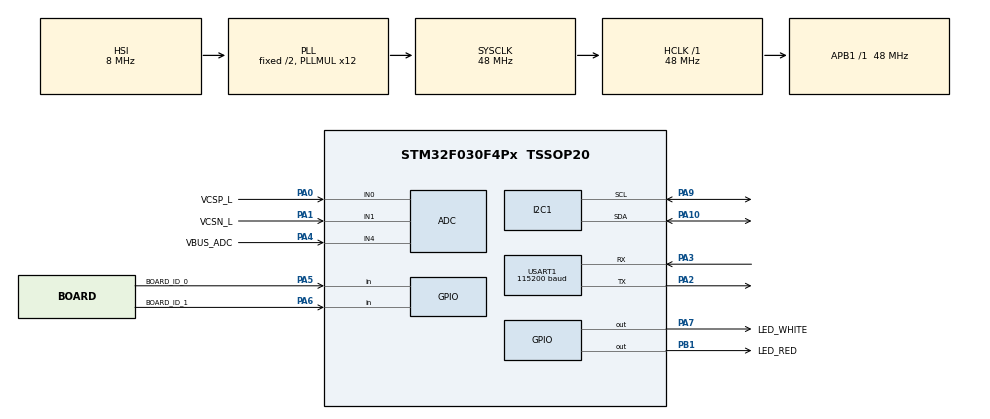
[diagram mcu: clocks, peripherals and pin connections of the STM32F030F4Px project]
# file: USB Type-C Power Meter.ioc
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ADC.SamplingTime=ADC_SAMPLETIME_239CYCLES_5
Mcu.Family=STM32F0
Mcu.Name=STM32F030F4Px
Mcu.Package=TSSOP20
PA0.GPIO_Label=VCSP_L
PA0.Mode=IN0
PA0.Signal=ADC_IN0
PA1.GPIO_Label=VCSN_L
PA1.Mode=IN1
PA1.Signal=ADC_IN1
PA10.Mode=I2C
PA10.Signal=I2C1_SDA
PA13.Mode=Serial_Wire
PA13.Signal=SYS_SWDIO
PA14.Mode=Serial_Wire
PA14.Signal=SYS_SWCLK
PA2.Mode=Asynchronous
PA2.Signal=USART1_TX
PA3.Mode=Asynchronous
PA3.Signal=USART1_RX
PA4.GPIO_Label=VBUS_ADC
PA4.Mode=IN4
PA4.Signal=ADC_IN4
PA5.GPIO_Label=BOARD_ID_0
PA5.Signal=GPIO_Input
PA6.GPIO_Label=BOARD_ID_1
PA6.Signal=GPIO_Input
PA7.GPIO_Label=LED_WHITE
PA7.Signal=GPIO_Output
PA9.Mode=I2C
PA9.Signal=I2C1_SCL
PB1.GPIO_Label=LED_RED
PB1.Signal=GPIO_Output
ProjectManager.HeapSize=0x200
ProjectManager.StackSize=0x400
ProjectManager.TargetToolchain=Makefile
RCC.AHBFreq_Value=48000000
RCC.APB1Freq_Value=48000000
RCC.APB1TimFreq_Value=48000000
RCC.HCLKFreq_Value=48000000
RCC.PLLMUL=RCC_PLL_MUL12
RCC.SYSCLKFreq_VALUE=48000000
RCC.SYSCLKSource=RCC_SYSCLKSOURCE_PLLCLK
USART1.BaudRate=115200
USART1.VirtualMode-Asynchronous=VM_ASYNC
board=custom

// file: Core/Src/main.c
/* USER CODE BEGIN Header */
/**
  ******************************************************************************
  * @file           : main.c
  * @brief          : Main program body
  ******************************************************************************
  * @attention
  *
  * Copyright (c) 2022 STMicroelectronics.
  * All rights reserved.
  *
  * This software is licensed under terms that can be found in the LICENSE file
  * in the root directory of this software component.
  * If no LICENSE file comes with this software, it is provided AS-IS.
  *
  ******************************************************************************
  */
/* USER CODE END Header */
#include "main.h"

/* USER CODE BEGIN Includes */
#include "board.h"
#include "light_rcc_init.h"
/* USER CODE END Includes */

/* USER CODE BEGIN PM */

I2C_HandleTypeDef hi2c1;

#if defined(UART_DEBUG) && !defined(UART_DEBUG_GPIO)
UART_HandleTypeDef huart1;
#endif

#if !defined(FIXED_SKUID) || (SKUID == SKUID_1)
ADC_HandleTypeDef hadc;
#endif

#if 0
/* USER CODE END PM */

ADC_HandleTypeDef hadc;

I2C_HandleTypeDef hi2c1;

UART_HandleTypeDef huart1;

/* USER CODE BEGIN PV */
#endif
/* USER CODE END PV */

void SystemClock_Config(void);
static void MX_GPIO_Init(void);
static void MX_ADC_Init(void);
static void MX_I2C1_Init(void);
static void MX_USART1_UART_Init(void);

/* USER CODE BEGIN 0 */
#include <stdio.h>
#include <string.h>
/* USER CODE END 0 */

int main(void)
{

  /* MCU Configuration--------------------------------------------------------*/

  /* Reset of all peripherals, Initializes the Flash interface and the Systick. */
  HAL_Init();

  /* USER CODE BEGIN Init */
#ifndef CONFIG_LIGHT_RCC_INIT
  /* USER CODE END Init */

  /* Configure the system clock */
  SystemClock_Config();

  /* USER CODE BEGIN SysInit */
#else
  Light_SystemClock_Config();
#endif
  /* USER CODE END SysInit */

  /* Initialize all configured peripherals */
  MX_GPIO_Init();
  MX_ADC_Init();
  MX_I2C1_Init();
  MX_USART1_UART_Init();
  /* USER CODE BEGIN 2 */

  BOARD_Init();
  PRINTF("Init Done\r\n");

  int tick_loop = HAL_GetTick();

#ifdef CONFIG_LED_NORMAL
  int tick_led = HAL_GetTick();
#endif
  /* USER CODE END 2 */

  /* Infinite loop */
  while (1)
  {

    /* USER CODE BEGIN 3 */
    if((HAL_GetTick() - tick_loop) >= CONFIG_BOARD_LOOP_TIME_MS) {
      tick_loop = HAL_GetTick();
      BOARD_Loop();
    }

#ifdef CONFIG_LED_NORMAL
    if((HAL_GetTick() - tick_led) >= CONFIG_LED_NORMAL_BLINK_MS) {
      tick_led = HAL_GetTick();
      HAL_GPIO_TogglePin(LED_BLUE_GPIO_Port, LED_BLUE_Pin);
    }
#endif

  }
  /* USER CODE END 3 */
}

void SystemClock_Config(void)
{
  RCC_OscInitTypeDef RCC_OscInitStruct = {0};
  RCC_ClkInitTypeDef RCC_ClkInitStruct = {0};
  RCC_PeriphCLKInitTypeDef PeriphClkInit = {0};

  /** Initializes the RCC Oscillators according to the specified parameters
  * in the RCC_OscInitTypeDef structure.
  */
  RCC_OscInitStruct.OscillatorType = RCC_OSCILLATORTYPE_HSI|RCC_OSCILLATORTYPE_HSI14;
  RCC_OscInitStruct.HSIState = RCC_HSI_ON;
  RCC_OscInitStruct.HSI14State = RCC_HSI14_ON;
  RCC_OscInitStruct.HSICalibrationValue = RCC_HSICALIBRATION_DEFAULT;
  RCC_OscInitStruct.HSI14CalibrationValue = 16;
  RCC_OscInitStruct.PLL.PLLState = RCC_PLL_ON;
  RCC_OscInitStruct.PLL.PLLSource = RCC_PLLSOURCE_HSI;
  RCC_OscInitStruct.PLL.PLLMUL = RCC_PLL_MUL12;
  RCC_OscInitStruct.PLL.PREDIV = RCC_PREDIV_DIV1;
  if (HAL_RCC_OscConfig(&RCC_OscInitStruct) != HAL_OK)
  {
    Error_Handler();
  }

  /** Initializes the CPU, AHB and APB buses clocks
  */
  RCC_ClkInitStruct.ClockType = RCC_CLOCKTYPE_HCLK|RCC_CLOCKTYPE_SYSCLK
                              |RCC_CLOCKTYPE_PCLK1;
  RCC_ClkInitStruct.SYSCLKSource = RCC_SYSCLKSOURCE_PLLCLK;
  RCC_ClkInitStruct.AHBCLKDivider = RCC_SYSCLK_DIV1;
  RCC_ClkInitStruct.APB1CLKDivider = RCC_HCLK_DIV1;

  if (HAL_RCC_ClockConfig(&RCC_ClkInitStruct, FLASH_LATENCY_1) != HAL_OK)
  {
    Error_Handler();
  }
  PeriphClkInit.PeriphClockSelection = RCC_PERIPHCLK_USART1|RCC_PERIPHCLK_I2C1;
  PeriphClkInit.Usart1ClockSelection = RCC_USART1CLKSOURCE_PCLK1;
  PeriphClkInit.I2c1ClockSelection = RCC_I2C1CLKSOURCE_HSI;
  if (HAL_RCCEx_PeriphCLKConfig(&PeriphClkInit) != HAL_OK)
  {
    Error_Handler();
  }
}

static void MX_ADC_Init(void)
{

  /* USER CODE BEGIN ADC_Init 0 */
#if !defined(FIXED_SKUID) || (SKUID == SKUID_1)
#ifdef ADC_INIT_CONFIG_TEST
  /* USER CODE END ADC_Init 0 */

  ADC_ChannelConfTypeDef sConfig = {0};
#endif

  /** Configure the global features of the ADC (Clock, Resolution, Data Alignment and number of conversion)
  */
  hadc.Instance = ADC1;
  hadc.Init.ClockPrescaler = ADC_CLOCK_ASYNC_DIV1;
  hadc.Init.Resolution = ADC_RESOLUTION_12B;
  hadc.Init.DataAlign = ADC_DATAALIGN_RIGHT;
  hadc.Init.ScanConvMode = ADC_SCAN_DIRECTION_FORWARD;
  hadc.Init.EOCSelection = ADC_EOC_SINGLE_CONV;
  hadc.Init.LowPowerAutoWait = DISABLE;
  hadc.Init.LowPowerAutoPowerOff = DISABLE;
  hadc.Init.ContinuousConvMode = DISABLE;
  hadc.Init.DiscontinuousConvMode = DISABLE;
  hadc.Init.ExternalTrigConv = ADC_SOFTWARE_START;
  hadc.Init.ExternalTrigConvEdge = ADC_EXTERNALTRIGCONVEDGE_NONE;
  hadc.Init.DMAContinuousRequests = DISABLE;
  hadc.Init.Overrun = ADC_OVR_DATA_PRESERVED;
  if (HAL_ADC_Init(&hadc) != HAL_OK)
  {
    Error_Handler();
  }
#ifdef ADC_INIT_CONFIG_TEST
  /** Configure for the selected ADC regular channel to be converted.
  */
  sConfig.Channel = ADC_CHANNEL_0;
  sConfig.Rank = ADC_RANK_CHANNEL_NUMBER;
  sConfig.SamplingTime = ADC_SAMPLETIME_239CYCLES_5;
  if (HAL_ADC_ConfigChannel(&hadc, &sConfig) != HAL_OK)
  {
    Error_Handler();
  }

  /** Configure for the selected ADC regular channel to be converted.
  */
  sConfig.Channel = ADC_CHANNEL_1;
  if (HAL_ADC_ConfigChannel(&hadc, &sConfig) != HAL_OK)
  {
    Error_Handler();
  }

  /** Configure for the selected ADC regular channel to be converted.
  */
  sConfig.Channel = ADC_CHANNEL_4;
  if (HAL_ADC_ConfigChannel(&hadc, &sConfig) != HAL_OK)
  {
    Error_Handler();
  }
  /* USER CODE BEGIN ADC_Init 2 */
#endif /* ADC_INIT_CONFIG_TEST */
#endif /* !defined(FIXED_SKUID) || (SKUID == SKUID_1) */
  /* USER CODE END ADC_Init 2 */

}

static void MX_I2C1_Init(void)
{

  hi2c1.Instance = I2C1;
  hi2c1.Init.Timing = 0x2000090E;
  hi2c1.Init.OwnAddress1 = 0;
  hi2c1.Init.AddressingMode = I2C_ADDRESSINGMODE_7BIT;
  hi2c1.Init.DualAddressMode = I2C_DUALADDRESS_DISABLE;
  hi2c1.Init.OwnAddress2 = 0;
  hi2c1.Init.OwnAddress2Masks = I2C_OA2_NOMASK;
  hi2c1.Init.GeneralCallMode = I2C_GENERALCALL_DISABLE;
  hi2c1.Init.NoStretchMode = I2C_NOSTRETCH_DISABLE;
  if (HAL_I2C_Init(&hi2c1) != HAL_OK)
  {
    Error_Handler();
  }

  /** Configure Analogue filter
  */
  if (HAL_I2CEx_ConfigAnalogFilter(&hi2c1, I2C_ANALOGFILTER_ENABLE) != HAL_OK)
  {
    Error_Handler();
  }

  /** Configure Digital filter
  */
  if (HAL_I2CEx_ConfigDigitalFilter(&hi2c1, 0) != HAL_OK)
  {
    Error_Handler();
  }

}

static void MX_USART1_UART_Init(void)
{

  /* USER CODE BEGIN USART1_Init 0 */
#if defined(UART_DEBUG) && !defined(UART_DEBUG_GPIO)
  /* USER CODE END USART1_Init 0 */

  huart1.Instance = USART1;
  huart1.Init.BaudRate = 115200;
  huart1.Init.WordLength = UART_WORDLENGTH_8B;
  huart1.Init.StopBits = UART_STOPBITS_1;
  huart1.Init.Parity = UART_PARITY_NONE;
  huart1.Init.Mode = UART_MODE_TX_RX;
  huart1.Init.HwFlowCtl = UART_HWCONTROL_NONE;
  huart1.Init.OverSampling = UART_OVERSAMPLING_16;
  huart1.Init.OneBitSampling = UART_ONE_BIT_SAMPLE_DISABLE;
  huart1.AdvancedInit.AdvFeatureInit = UART_ADVFEATURE_NO_INIT;
  if (HAL_UART_Init(&huart1) != HAL_OK)
  {
    Error_Handler();
  }
  /* USER CODE BEGIN USART1_Init 2 */
#else
  return;
#endif
  /* USER CODE END USART1_Init 2 */

}

static void MX_GPIO_Init(void)
{
  GPIO_InitTypeDef GPIO_InitStruct = {0};

  /* GPIO Ports Clock Enable */
  __HAL_RCC_GPIOA_CLK_ENABLE();
  __HAL_RCC_GPIOB_CLK_ENABLE();

  /*Configure GPIO pin Output Level */
  HAL_GPIO_WritePin(GPIOA, GPIO_PIN_7, GPIO_PIN_RESET);

  /*Configure GPIO pin Output Level */
  HAL_GPIO_WritePin(GPIOB, GPIO_PIN_1, GPIO_PIN_RESET);

  /*Configure GPIO pins : PA5 PA6 */
  GPIO_InitStruct.Pin = GPIO_PIN_5|GPIO_PIN_6;
  GPIO_InitStruct.Mode = GPIO_MODE_INPUT;
  GPIO_InitStruct.Pull = GPIO_NOPULL;
  HAL_GPIO_Init(GPIOA, &GPIO_InitStruct);

  /*Configure GPIO pin : PA7 */
  GPIO_InitStruct.Pin = GPIO_PIN_7;
  GPIO_InitStruct.Mode = GPIO_MODE_OUTPUT_PP;
  GPIO_InitStruct.Pull = GPIO_NOPULL;
  GPIO_InitStruct.Speed = GPIO_SPEED_FREQ_LOW;
  HAL_GPIO_Init(GPIOA, &GPIO_InitStruct);

  /*Configure GPIO pin : PB1 */
  GPIO_InitStruct.Pin = GPIO_PIN_1;
  GPIO_InitStruct.Mode = GPIO_MODE_OUTPUT_PP;
  GPIO_InitStruct.Pull = GPIO_NOPULL;
  GPIO_InitStruct.Speed = GPIO_SPEED_FREQ_LOW;
  HAL_GPIO_Init(GPIOB, &GPIO_InitStruct);

#if defined(UART_DEBUG) && defined(UART_DEBUG_GPIO)

  /*Configure GPIO pin Output Level */
  HAL_GPIO_WritePin(GPIO_UART_Port, GPIO_UART_Pin, GPIO_PIN_SET);

  /*Configure GPIO pin : PA2 */
  GPIO_InitStruct.Pin = GPIO_UART_Pin;
  GPIO_InitStruct.Mode = GPIO_MODE_OUTPUT_PP;
  GPIO_InitStruct.Pull = GPIO_NOPULL;
  GPIO_InitStruct.Speed = GPIO_SPEED_FREQ_MEDIUM;
  HAL_GPIO_Init(GPIO_UART_Port, &GPIO_InitStruct);

#endif /* defined(UART_DEBUG) && defined(UART_DEBUG_GPIO) */
}

void Error_Handler(void)
{
  /* USER CODE BEGIN Error_Handler_Debug */
#ifdef CONFIG_LED_ERROR
  /* Get Start Tick */
  int tickstart = HAL_GetTick();
  while (1)
  {
    HAL_GPIO_TogglePin(LED_BLUE_GPIO_Port, LED_BLUE_Pin);
    HAL_Delay(CONFIG_LED_ERROR_BLINK_MS);

    if((HAL_GetTick() - tickstart) > CONFIG_LED_ERROR_TIME_MS)
      break;
  }
#endif

  /* User can add his own implementation to report the HAL error return state */
  __disable_irq();
  /* reset chip */
  HAL_NVIC_SystemReset();
  /* USER CODE END Error_Handler_Debug */
}
